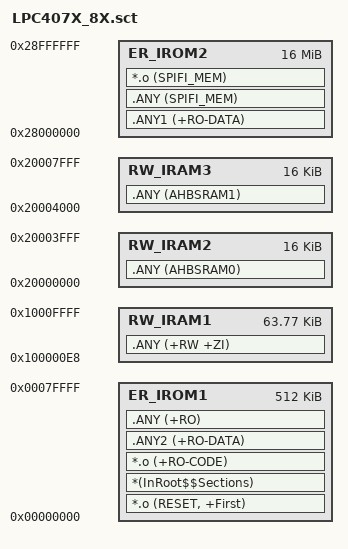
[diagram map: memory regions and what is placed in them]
; *************************************************************
; *** Scatter-Loading Description File generated by uVision ***
; *************************************************************

LR_IROM1 0x00000000 0x00080000  {    ; load region size_region
  ER_IROM1 0x00000000 0x00080000  {  ; load address = execution address
   *.o (RESET, +First)
   *(InRoot$$Sections)
   *.o (+RO-CODE)                    ; prioritizes CODE in IFLASH before SPIFI
   .ANY2 (+RO-DATA)                  ; prioritizes DATA in IFLASH before SPIFI
   .ANY (+RO)                        ; remaining RO
  }
  RW_IRAM1 0x100000E8 0x0000FF18  {  ; RW data
   .ANY (+RW +ZI)
  }
  RW_IRAM2 0x20000000 0x00004000  {
   .ANY (AHBSRAM0)
  }
  RW_IRAM3 0x20004000 0x00004000  {
   .ANY (AHBSRAM1)
  }
}

LR_IROM2 0x28000000 0x01000000  {
  ER_IROM2 0x28000000 0x01000000  {  ; load address = execution address
    .ANY1 (+RO-DATA)                 ; all DATA not fitting in IFLASH
    .ANY (SPIFI_MEM)                 ; DATA tagged as SPIFI_MEM
    *.o (SPIFI_MEM)                  ; CODE tagged as SPIFI_MEM
  }
}

